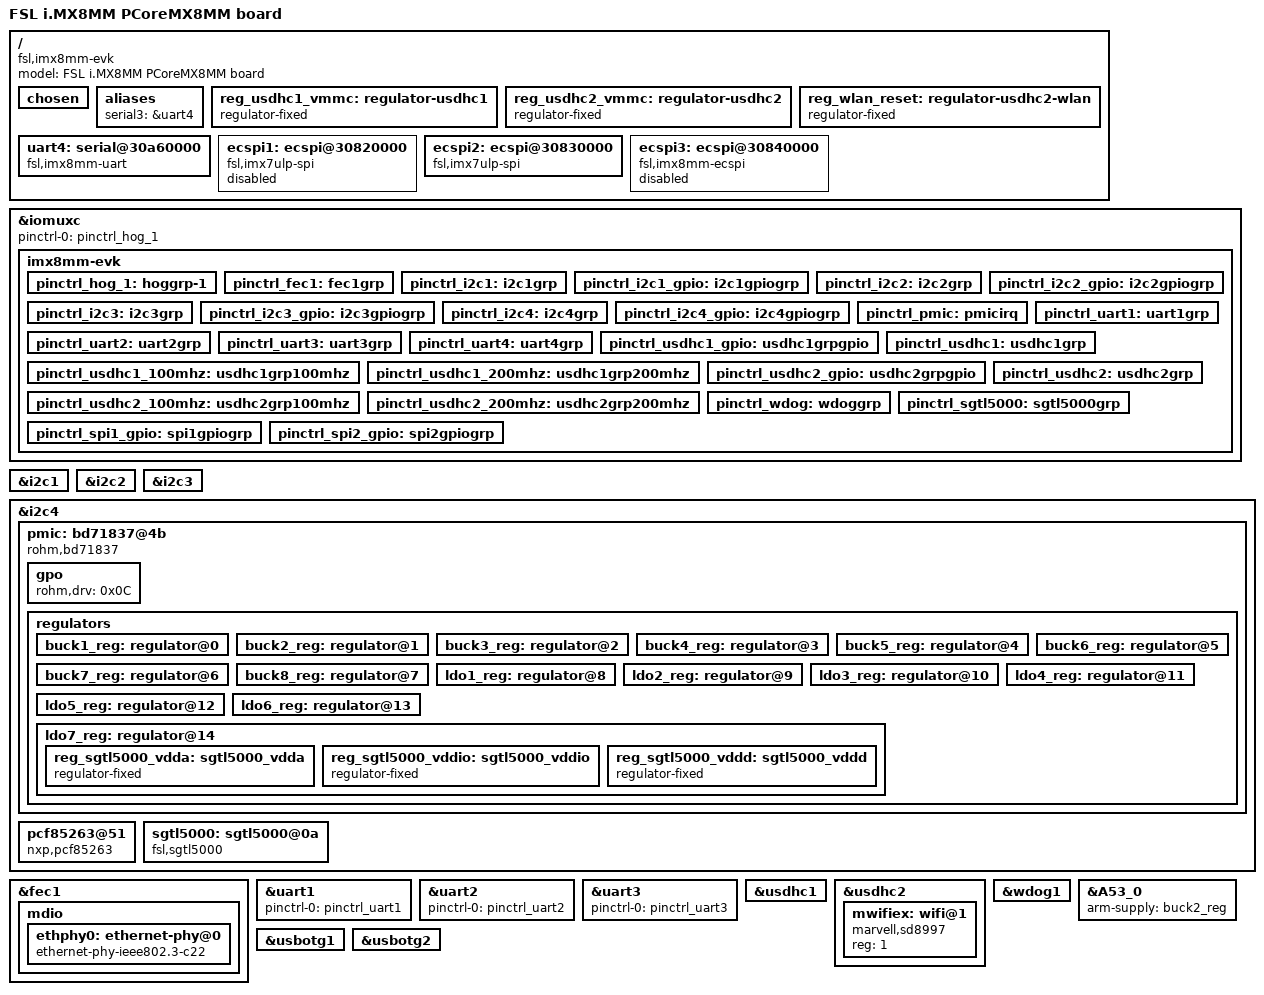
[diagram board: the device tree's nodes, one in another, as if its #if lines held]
/*
 * Copyright 2018 NXP
 *
 * This program is free software; you can redistribute it and/or
 * modify it under the terms of the GNU General Public License
 * as published by the Free Software Foundation; either version 2
 * of the License, or (at your option) any later version.
 *
 * This program is distributed in the hope that it will be useful,
 * but WITHOUT ANY WARRANTY; without even the implied warranty of
 * MERCHANTABILITY or FITNESS FOR A PARTICULAR PURPOSE.  See the
 * GNU General Public License for more details.
 */

/dts-v1/;

/* WLAN/BLUETOOTH; either WLAN-only or combined WLAN/Bluetooth chip */
#define CONFIG_PICOCOREMX8MM_WLAN

/* If WLAN is equipped, SD_B is not available */
#ifdef CONFIG_PICOCOREMX8MM_WLAN
#undef CONFIG_PICOCOREMX8MM_SD_B
#undef CONFIG_PICOCOREMX8MM_SD_B_CD
#undef CONFIG_PICOCOREMX8MM_SD_B_WP
#endif

#include "fsl-imx8mm.dtsi"

/ {

	model = "FSL i.MX8MM PCoreMX8MM board";
	compatible = "fsl,imx8mm-evk", "fsl,imx8mm";

	chosen {
		bootargs = "console=ttymxc1,115200 earlycon=ec_imx6q,0x30890000,115200";
		stdout-path = &uart2;
	};

	aliases {
		serial3 = &uart4;
	};

	reg_usdhc1_vmmc: regulator-usdhc1 {
		compatible = "regulator-fixed";
		regulator-name = "VSD1_3V3";
		regulator-min-microvolt = <3300000>;
		regulator-max-microvolt = <3300000>;
		gpio = <&gpio2 10 GPIO_ACTIVE_HIGH>;
		enable-active-high;
		startup-delay-us = <100>;
		off-on-delay-us = <12000>;
	};

	reg_usdhc2_vmmc: regulator-usdhc2 {
		compatible = "regulator-fixed";
		regulator-name = "VSD2_3V3";
		regulator-min-microvolt = <3300000>;
		regulator-max-microvolt = <3300000>;
		gpio = <&gpio2 19 GPIO_ACTIVE_HIGH>;
		enable-active-high;
		startup-delay-us = <100>;
		off-on-delay-us = <12000>;
	};

	reg_wlan_reset: regulator-usdhc2-wlan {
		compatible = "regulator-fixed";
		regulator-name = "WLAN_RESET";
		regulator-min-microvolt = <3300000>;
		regulator-max-microvolt = <3300000>;
		gpio = <&gpio3 20 GPIO_ACTIVE_HIGH>;
		off-on-delay = <1000>;
		enable-active-high;
	};

	uart4: serial@30a60000 {
		compatible = "fsl,imx8mm-uart",
			     "fsl,imx6q-uart", "fsl,imx21-uart";
		reg = <0x0 0x30a60000 0x0 0x10000>;
		interrupts = <GIC_SPI 29 IRQ_TYPE_LEVEL_HIGH>;
		clocks = <&clk IMX8MM_CLK_UART4_ROOT>,
			<&clk IMX8MM_CLK_UART4_ROOT>;
		clock-names = "ipg", "per";
		dmas = <&sdma1 28 4 0>, <&sdma1 29 4 0>;
		dma-names = "rx", "tx";
		status = "disabled";
	};
	ecspi1: ecspi@30820000 {
		#address-cells = <1>;
		#size-cells = <0>;
		compatible = "fsl,imx8mm-ecspi", "fsl,imx51-ecspi";
		reg = <0x0 0x30820000 0x0 0x10000>;
		interrupts = <GIC_SPI 31 IRQ_TYPE_LEVEL_HIGH>;
		clocks = <&clk IMX8MM_CLK_ECSPI1_ROOT>,
			<&clk IMX8MM_CLK_ECSPI1_ROOT>;
		clock-names = "ipg", "per";
		dmas = <&sdma1 0 7 1>, <&sdma1 1 7 2>;
		dma-names = "rx", "tx";
		status = "disabled";
	};

	ecspi2: ecspi@30830000 {
		#address-cells = <1>;
		#size-cells = <0>;
		compatible = "fsl,imx8mm-ecspi", "fsl,imx51-ecspi";
		reg = <0x0 0x30830000 0x0 0x10000>;
		interrupts = <GIC_SPI 32 IRQ_TYPE_LEVEL_HIGH>;
		clocks = <&clk IMX8MM_CLK_ECSPI2_ROOT>,
			<&clk IMX8MM_CLK_ECSPI2_ROOT>;
		clock-names = "ipg", "per";
		dmas = <&sdma1 2 7 1>, <&sdma1 3 7 2>;
		dma-names = "rx", "tx";
		status = "disabled";
	};

	ecspi3: ecspi@30840000 {
		#address-cells = <1>;
		#size-cells = <0>;
		compatible = "fsl,imx8mm-ecspi", "fsl,imx51-ecspi";
		reg = <0x0 0x30840000 0x0 0x10000>;
		interrupts = <GIC_SPI 33 IRQ_TYPE_LEVEL_HIGH>;
		clocks = <&clk IMX8MM_CLK_ECSPI3_ROOT>,
			<&clk IMX8MM_CLK_ECSPI3_ROOT>;
		clock-names = "ipg", "per";
		dmas = <&sdma1 4 7 1>, <&sdma1 5 7 2>;
		dma-names = "rx", "tx";
		status = "disabled";
	};
};

&iomuxc {
	pinctrl-names = "default";
	pinctrl-0 = <&pinctrl_hog_1>;

	imx8mm-evk {
		pinctrl_hog_1: hoggrp-1 {
			fsl,pins = <
				MX8MM_IOMUXC_GPIO1_IO08_GPIO1_IO8		0x19
				/* CLKO2 -> EXTCLK */
				MX8MM_IOMUXC_GPIO1_IO15_CCMSRCGPCMIX_CLKO2	0x59
			>;
		};

		pinctrl_fec1: fec1grp {
			fsl,pins = <
				MX8MM_IOMUXC_ENET_MDC_ENET1_MDC		0x3
				MX8MM_IOMUXC_ENET_MDIO_ENET1_MDIO	0x3
				MX8MM_IOMUXC_ENET_TD3_ENET1_RGMII_TD3	0x1f
				MX8MM_IOMUXC_ENET_TD2_ENET1_RGMII_TD2	0x1f
				MX8MM_IOMUXC_ENET_TD1_ENET1_RGMII_TD1	0x1f
				MX8MM_IOMUXC_ENET_TD0_ENET1_RGMII_TD0	0x1f
				MX8MM_IOMUXC_ENET_RD3_ENET1_RGMII_RD3	0x91
				MX8MM_IOMUXC_ENET_RD2_ENET1_RGMII_RD2	0x91
				MX8MM_IOMUXC_ENET_RD1_ENET1_RGMII_RD1	0x91
				MX8MM_IOMUXC_ENET_RD0_ENET1_RGMII_RD0	0x91
				MX8MM_IOMUXC_ENET_TXC_ENET1_RGMII_TXC	0x1f
				MX8MM_IOMUXC_ENET_RXC_ENET1_RGMII_RXC	0x91
				MX8MM_IOMUXC_ENET_RX_CTL_ENET1_RGMII_RX_CTL	0x91
				MX8MM_IOMUXC_ENET_TX_CTL_ENET1_RGMII_TX_CTL	0x1f
				MX8MM_IOMUXC_GPIO1_IO04_GPIO1_IO4	0x19
				MX8MM_IOMUXC_GPIO1_IO05_GPIO1_IO5	0x19
			>;
		};

		pinctrl_i2c1: i2c1grp {
			fsl,pins = <
				MX8MM_IOMUXC_I2C1_SCL_I2C1_SCL			0x400001c3
				MX8MM_IOMUXC_I2C1_SDA_I2C1_SDA			0x400001c3
			>;
		};

		pinctrl_i2c1_gpio: i2c1gpiogrp {
			fsl,pins = <
				MX8MM_IOMUXC_I2C1_SCL_GPIO5_IO14			0x119
				MX8MM_IOMUXC_I2C1_SDA_GPIO5_IO15			0x119
			>;
		};

		pinctrl_i2c2: i2c2grp {
			fsl,pins = <
				MX8MM_IOMUXC_I2C2_SCL_I2C2_SCL			0x400001c3
				MX8MM_IOMUXC_I2C2_SDA_I2C2_SDA			0x400001c3
			>;
		};

		pinctrl_i2c2_gpio: i2c2gpiogrp {
			fsl,pins = <
				MX8MM_IOMUXC_I2C2_SCL_GPIO5_IO16			0x119
				MX8MM_IOMUXC_I2C2_SDA_GPIO5_IO17			0x119
			>;
		};

		pinctrl_i2c3: i2c3grp {
			fsl,pins = <
				MX8MM_IOMUXC_I2C3_SCL_I2C3_SCL			0x400001c3
				MX8MM_IOMUXC_I2C3_SDA_I2C3_SDA			0x400001c3
			>;
		};

		pinctrl_i2c3_gpio: i2c3gpiogrp {
			fsl,pins = <
				MX8MM_IOMUXC_I2C3_SCL_GPIO5_IO18			0x119
				MX8MM_IOMUXC_I2C3_SDA_GPIO5_IO19			0x119
			>;
		};

		pinctrl_i2c4: i2c4grp {
			fsl,pins = <
				MX8MM_IOMUXC_I2C4_SCL_I2C4_SCL			0x400001c3
				MX8MM_IOMUXC_I2C4_SDA_I2C4_SDA			0x400001c3
			>;
		};

		pinctrl_i2c4_gpio: i2c4gpiogrp {
			fsl,pins = <
				MX8MM_IOMUXC_I2C4_SCL_GPIO5_IO20			0x119
				MX8MM_IOMUXC_I2C4_SDA_GPIO5_IO21			0x119
			>;
		};

		pinctrl_pmic: pmicirq {
			fsl,pins = <
				MX8MM_IOMUXC_SAI5_RXD3_GPIO3_IO24		0x41
			>;
		};


		pinctrl_uart1: uart1grp {
			fsl,pins = <
				MX8MM_IOMUXC_UART1_RXD_UART1_DCE_RX	0x49
				MX8MM_IOMUXC_UART1_TXD_UART1_DCE_TX	0x49
			>;
		};

		pinctrl_uart2: uart2grp {
			fsl,pins = <
				MX8MM_IOMUXC_UART2_RXD_UART2_DCE_RX	0x49
				MX8MM_IOMUXC_UART2_TXD_UART2_DCE_TX	0x49
			>;
		};

		pinctrl_uart3: uart3grp {
			fsl,pins = <
				MX8MM_IOMUXC_UART3_RXD_UART3_DCE_RX	0x49
				MX8MM_IOMUXC_UART3_TXD_UART3_DCE_TX	0x49
			>;
		};

		pinctrl_uart4: uart4grp {
			fsl,pins = <
				MX8MM_IOMUXC_UART4_RXD_UART4_DCE_RX	0x49
				MX8MM_IOMUXC_UART4_TXD_UART4_DCE_TX	0x49
			>;
		};

       pinctrl_usdhc1_gpio: usdhc1grpgpio {
			fsl,pins = <
                MX8MM_IOMUXC_GPIO1_IO06_USDHC1_CD_B	0x41
				MX8MM_IOMUXC_SD1_RESET_B_GPIO2_IO10	0x41
			>;
		};

		pinctrl_usdhc1: usdhc1grp {
			fsl,pins = <
				MX8MM_IOMUXC_SD1_CLK_USDHC1_CLK		0x190
				MX8MM_IOMUXC_SD1_CMD_USDHC1_CMD		0x1d0
				MX8MM_IOMUXC_SD1_DATA0_USDHC1_DATA0	0x1d0
				MX8MM_IOMUXC_SD1_DATA1_USDHC1_DATA1	0x1d0
				MX8MM_IOMUXC_SD1_DATA2_USDHC1_DATA2	0x1d0
				MX8MM_IOMUXC_SD1_DATA3_USDHC1_DATA3	0x1d0
				MX8MM_IOMUXC_GPIO1_IO03_USDHC1_VSELECT	0x1d0
			>;
		};

		pinctrl_usdhc1_100mhz: usdhc1grp100mhz {
			fsl,pins = <
				MX8MM_IOMUXC_SD1_CLK_USDHC1_CLK		0x194
				MX8MM_IOMUXC_SD1_CMD_USDHC1_CMD		0x1d4
				MX8MM_IOMUXC_SD1_DATA0_USDHC1_DATA0	0x1d4
				MX8MM_IOMUXC_SD1_DATA1_USDHC1_DATA1	0x1d4
				MX8MM_IOMUXC_SD1_DATA2_USDHC1_DATA2	0x1d4
				MX8MM_IOMUXC_SD1_DATA3_USDHC1_DATA3	0x1d4
				MX8MM_IOMUXC_GPIO1_IO03_USDHC1_VSELECT	0x1d0
			>;
		};

		pinctrl_usdhc1_200mhz: usdhc1grp200mhz {
			fsl,pins = <
				MX8MM_IOMUXC_SD1_CLK_USDHC1_CLK		0x196
				MX8MM_IOMUXC_SD1_CMD_USDHC1_CMD		0x1d6
				MX8MM_IOMUXC_SD1_DATA0_USDHC1_DATA0	0x1d6
				MX8MM_IOMUXC_SD1_DATA1_USDHC1_DATA1	0x1d6
				MX8MM_IOMUXC_SD1_DATA2_USDHC1_DATA2	0x1d6
				MX8MM_IOMUXC_SD1_DATA3_USDHC1_DATA3	0x1d6
				MX8MM_IOMUXC_GPIO1_IO03_USDHC1_VSELECT	0x1d0
			>;
		};

		pinctrl_usdhc2_gpio: usdhc2grpgpio {
			fsl,pins = <
                MX8MM_IOMUXC_SD2_CD_B_GPIO2_IO12    0x41
				MX8MM_IOMUXC_SD2_RESET_B_GPIO2_IO19	0x41
			//	MX8MM_IOMUXC_SAI5_RXC_GPIO3_IO20	0x41
			>;
		};

		pinctrl_usdhc2: usdhc2grp {
			fsl,pins = <
				MX8MM_IOMUXC_SD2_CLK_USDHC2_CLK		0x190
				MX8MM_IOMUXC_SD2_CMD_USDHC2_CMD		0x1d0
				MX8MM_IOMUXC_SD2_DATA0_USDHC2_DATA0	0x1d0
				MX8MM_IOMUXC_SD2_DATA1_USDHC2_DATA1	0x1d0
				MX8MM_IOMUXC_SD2_DATA2_USDHC2_DATA2	0x1d0
				MX8MM_IOMUXC_SD2_DATA3_USDHC2_DATA3	0x1d0
				MX8MM_IOMUXC_GPIO1_IO04_USDHC2_VSELECT	0x1d0
			>;
		};

		pinctrl_usdhc2_100mhz: usdhc2grp100mhz {
			fsl,pins = <
				MX8MM_IOMUXC_SD2_CLK_USDHC2_CLK		0x194
				MX8MM_IOMUXC_SD2_CMD_USDHC2_CMD		0x1d4
				MX8MM_IOMUXC_SD2_DATA0_USDHC2_DATA0	0x1d4
				MX8MM_IOMUXC_SD2_DATA1_USDHC2_DATA1	0x1d4
				MX8MM_IOMUXC_SD2_DATA2_USDHC2_DATA2	0x1d4
				MX8MM_IOMUXC_SD2_DATA3_USDHC2_DATA3	0x1d4
				MX8MM_IOMUXC_GPIO1_IO04_USDHC2_VSELECT	0x1d0
			>;
		};

		pinctrl_usdhc2_200mhz: usdhc2grp200mhz {
			fsl,pins = <
				MX8MM_IOMUXC_SD2_CLK_USDHC2_CLK		0x196
				MX8MM_IOMUXC_SD2_CMD_USDHC2_CMD		0x1d6
				MX8MM_IOMUXC_SD2_DATA0_USDHC2_DATA0	0x1d6
				MX8MM_IOMUXC_SD2_DATA1_USDHC2_DATA1	0x1d6
				MX8MM_IOMUXC_SD2_DATA2_USDHC2_DATA2	0x1d6
				MX8MM_IOMUXC_SD2_DATA3_USDHC2_DATA3	0x1d6
				MX8MM_IOMUXC_GPIO1_IO04_USDHC2_VSELECT	0x1d0
			>;
		};


		pinctrl_wdog: wdoggrp {
			fsl,pins = <
				MX8MM_IOMUXC_SAI1_RXD7_GPIO4_IO9		0xc6
			>;
		};

		pinctrl_sgtl5000: sgtl5000grp {
			fsl,pins = <
				MX8MM_IOMUXC_SAI1_MCLK_SAI1_MCLK		0x000d6
				MX8MM_IOMUXC_SAI1_TXFS_SAI1_TX_SYNC		0x000d6
				MX8MM_IOMUXC_SAI1_TXC_SAI1_TX_BCLK		0x000d6
				MX8MM_IOMUXC_SAI1_TXD0_SAI1_TX_DATA0		0x000d6
				MX8MM_IOMUXC_SAI1_RXD0_SAI1_RX_DATA0		0x000d6
			>;
		};


		pinctrl_spi1_gpio: spi1gpiogrp {
            fsl,pins = <

                MX8MM_IOMUXC_ECSPI1_SCLK_GPIO5_IO6    0x119
                MX8MM_IOMUXC_ECSPI1_MOSI_GPIO5_IO7    0x119
                MX8MM_IOMUXC_ECSPI1_MISO_GPIO5_IO8    0x119
                MX8MM_IOMUXC_ECSPI1_SS0_GPIO5_IO9     0x119
            >;
        };
            pinctrl_spi2_gpio: spi2gpiogrp {
            fsl,pins = <

                MX8MM_IOMUXC_ECSPI2_SCLK_GPIO5_IO10    0x119
                MX8MM_IOMUXC_ECSPI2_MOSI_GPIO5_IO11    0x119
                MX8MM_IOMUXC_ECSPI2_MISO_GPIO5_IO12    0x119
                MX8MM_IOMUXC_ECSPI2_SS0_GPIO5_IO13     0x119
            >;
        };

	};
};

&i2c1 {
	clock-frequency = <400000>;
    pinctrl-names = "default", "gpiotest";
    pinctrl-0 = <&pinctrl_i2c1>;
	pinctrl-1 = <&pinctrl_i2c1_gpio>;
    out-pins = "I2C_A_SCL";
    out-gpios = <&gpio5 14 0>;
    in-pins = "I2C_A_SDA";
    in-gpios = <&gpio5 15 0>;
    status = "okay";
};

&i2c2 {
	clock-frequency = <400000>;
	pinctrl-names = "default";
	pinctrl-0 = <&pinctrl_i2c2>;
	pinctrl-1 = <&pinctrl_i2c2_gpio>;
    out-pins = "I2C_B_SCL";
    out-gpios = <&gpio5 16 0>;
    in-pins = "I2C_B_SDA";
    in-gpios = <&gpio5 17 0>;
	status = "okay";
};

&i2c3 {
	clock-frequency = <100000>;
	pinctrl-names = "default";
	pinctrl-0 = <&pinctrl_i2c3>;
	pinctrl-1 = <&pinctrl_i2c3_gpio>;
    out-pins = "I2C_C_SCL";
    out-gpios = <&gpio5 18 0>;
    in-pins = "I2C_C_SDA";
    in-gpios = <&gpio5 19 0>;
	status = "okay";
};

&i2c4 {
	clock-frequency = <400000>;
	pinctrl-names = "default";
	pinctrl-0 = <&pinctrl_i2c4>;
	pinctrl-1 = <&pinctrl_i2c4_gpio>;
    out-pins = "I2C_D_SCL";
    out-gpios = <&gpio5 20 0>;
    in-pins = "I2C_D_SDA";
    in-gpios = <&gpio5 21 0>;
	status = "okay";

	pmic: bd71837@4b {
		reg = <0x4b>;
		compatible = "rohm,bd71837";
		/* PMIC BD71837 PMIC_nINT GPIO3_IO24 */
		pinctrl-0 = <&pinctrl_pmic>;
		gpio_intr = <&gpio3 24 GPIO_ACTIVE_LOW>;
		status = "okay";

		gpo {
			rohm,drv = <0x0C>;	/* 0b0000_1100 all gpos with cmos output mode */
		};

		regulators {
			#address-cells = <1>;
			#size-cells = <0>;

			bd71837,pmic-buck2-uses-i2c-dvs;
			bd71837,pmic-buck2-dvs-voltage = <1000000>, <900000>, <0>; /* VDD_ARM: Run-Idle */

			buck1_reg: regulator@0 {
				reg = <0>;
				regulator-compatible = "buck1";
				regulator-min-microvolt = <700000>;
				regulator-max-microvolt = <1300000>;
				regulator-boot-on;
				regulator-always-on;
				regulator-ramp-delay = <1250>;
			};

			buck2_reg: regulator@1 {
				reg = <1>;
				regulator-compatible = "buck2";
				regulator-min-microvolt = <700000>;
				regulator-max-microvolt = <1300000>;
				regulator-boot-on;
				regulator-always-on;
				regulator-ramp-delay = <1250>;
			};

			buck3_reg: regulator@2 {
				reg = <2>;
				regulator-compatible = "buck3";
				regulator-min-microvolt = <700000>;
				regulator-max-microvolt = <1300000>;
			};

			buck4_reg: regulator@3 {
				reg = <3>;
				regulator-compatible = "buck4";
				regulator-min-microvolt = <700000>;
				regulator-max-microvolt = <1300000>;
			};

			buck5_reg: regulator@4 {
				reg = <4>;
				regulator-compatible = "buck5";
				regulator-min-microvolt = <700000>;
				regulator-max-microvolt = <1350000>;
				regulator-boot-on;
				regulator-always-on;
			};

			buck6_reg: regulator@5 {
				reg = <5>;
				regulator-compatible = "buck6";
				regulator-min-microvolt = <3000000>;
				regulator-max-microvolt = <3300000>;
				regulator-boot-on;
				regulator-always-on;
			};

			buck7_reg: regulator@6 {
				reg = <6>;
				regulator-compatible = "buck7";
				regulator-min-microvolt = <1605000>;
				regulator-max-microvolt = <1995000>;
				regulator-boot-on;
				regulator-always-on;
			};

			buck8_reg: regulator@7 {
				reg = <7>;
				regulator-compatible = "buck8";
				regulator-min-microvolt = <800000>;
				regulator-max-microvolt = <1400000>;
				regulator-boot-on;
				regulator-always-on;
			};

			ldo1_reg: regulator@8 {
				reg = <8>;
				regulator-compatible = "ldo1";
				regulator-min-microvolt = <3000000>;
				regulator-max-microvolt = <3300000>;
				regulator-boot-on;
				regulator-always-on;
			};

			ldo2_reg: regulator@9 {
				reg = <9>;
				regulator-compatible = "ldo2";
				regulator-min-microvolt = <900000>;
				regulator-max-microvolt = <900000>;
				regulator-boot-on;
				regulator-always-on;
			};

			ldo3_reg: regulator@10 {
				reg = <10>;
				regulator-compatible = "ldo3";
				regulator-min-microvolt = <1800000>;
				regulator-max-microvolt = <3300000>;
				regulator-boot-on;
				regulator-always-on;
			};

			ldo4_reg: regulator@11 {
				reg = <11>;
				regulator-compatible = "ldo4";
				regulator-min-microvolt = <900000>;
				regulator-max-microvolt = <1800000>;
				regulator-boot-on;
				regulator-always-on;
			};

			ldo5_reg: regulator@12 {
				reg = <12>;
				regulator-compatible = "ldo5";
				regulator-min-microvolt = <1800000>;
				regulator-max-microvolt = <3300000>;
			};

			ldo6_reg: regulator@13 {
				reg = <13>;
				regulator-compatible = "ldo6";
				regulator-min-microvolt = <900000>;
				regulator-max-microvolt = <1800000>;
				regulator-boot-on;
				regulator-always-on;
			};

			ldo7_reg: regulator@14 {
				reg = <14>;
				regulator-compatible = "ldo7";
				regulator-min-microvolt = <1800000>;
				regulator-max-microvolt = <3300000>;
			/* SGTL5000 analog voltage */
			reg_sgtl5000_vdda: sgtl5000_vdda {
				compatible = "regulator-fixed";
				regulator-name = "VDDA-supply";
				regulator-min-microvolt = <3000000>;
				regulator-max-microvolt = <3000000>;
				regulator-always-on;
			};

			/* SGTL5000 I/O voltage */
			reg_sgtl5000_vddio: sgtl5000_vddio {
				compatible = "regulator-fixed";
				regulator-name = "VDDIO-supply";
				regulator-min-microvolt = <3300000>;
				regulator-max-microvolt = <3300000>;
				regulator-always-on;
			};

			/* SGTL5000 internal digital voltage */
			reg_sgtl5000_vddd: sgtl5000_vddd {
				compatible = "regulator-fixed";
				regulator-name = "VDDD-supply";
				regulator-min-microvolt = <1500000>;
				regulator-max-microvolt = <1500000>;
				regulator-always-on;
			};
			};
		};
	};

	pcf85263@51 {
 		compatible = "nxp,pcf85263";
		quartz-load-capacitance = <0x2>; /* 12.5 pF */
		reg = <0x51>;
		status = "okay";
	};

	sgtl5000: sgtl5000@0a {
		compatible = "fsl,sgtl5000";
		/* MCLK is needed for i2c sgtl driver */
		pinctrl-names = "default";
		pinctrl-0 = <&pinctrl_sgtl5000>;
		reg = <0x0a>;
		status = "okay";
	};
};

&fec1 {
	pinctrl-names = "default";
	pinctrl-0 = <&pinctrl_fec1>;
	phy-mode = "rgmii-id";
	phy-handle = <&ethphy0>;
	fsl,magic-packet;
	status = "okay";
    phy-reset-gpios = <&gpio1 5 GPIO_ACTIVE_LOW>;
    phy-reset-duration = <50>;
    phy-reset-post-delay = <200>;


	mdio {
		#address-cells = <1>;
		#size-cells = <0>;

		ethphy0: ethernet-phy@0 {
			compatible = "ethernet-phy-ieee802.3-c22";
			reg = <0>;
			at803x,led-act-blind-workaround;
			at803x,eee-okay;
#if 0
			at803x,vddio-1p8v;
#endif
		};
	};
};

&uart1 { /* console */
	pinctrl-names = "default";
	pinctrl-0 = <&pinctrl_uart1>;
	status = "okay";
};

&uart2 { /* console */
	pinctrl-names = "default";
	pinctrl-0 = <&pinctrl_uart2>;
	status = "okay";
};

&uart3 { /* console */
	pinctrl-names = "default";
	pinctrl-0 = <&pinctrl_uart3>;
	status = "okay";
};

&uart4 { /* console */
	pinctrl-names = "default";
	pinctrl-0 = <&pinctrl_uart4>;
	status = "okay";
};

&usdhc1 {
	pinctrl-names = "default", "state_100mhz", "state_200mhz";
	pinctrl-0 = <&pinctrl_usdhc1>, <&pinctrl_usdhc1_gpio>;
	pinctrl-1 = <&pinctrl_usdhc1_100mhz>, <&pinctrl_usdhc1_gpio>;
	pinctrl-2 = <&pinctrl_usdhc1_200mhz>, <&pinctrl_usdhc1_gpio>;
	bus-width = <4>;
	cd-gpios = <&gpio1 6 GPIO_ACTIVE_LOW>;
	vmmc-supply = <&reg_usdhc1_vmmc>;
	is-sdcard;
	status = "okay";
};

/* WLAN */
#if defined(CONFIG_PICOCOREMX8MM_WLAN) || defined(CONFIG_PICOCOREMX8MM_SD_B)
&usdhc2 {
	pinctrl-names = "default", "state_100mhz", "state_200mhz";
	pinctrl-0 = <&pinctrl_usdhc2>, <&pinctrl_usdhc2_gpio>;
	pinctrl-1 = <&pinctrl_usdhc2_100mhz>, <&pinctrl_usdhc2_gpio>;
	pinctrl-2 = <&pinctrl_usdhc2_200mhz>, <&pinctrl_usdhc2_gpio>;
#ifdef CONFIG_PICOCOREMX8MM_SD_B_CD
	cd-gpios = <&gpio2 12 GPIO_ACTIVE_LOW>;
#else
	non-removable;
#endif
#ifdef CONFIG_PICOCOREMX8MM_SD_B_WP
	wp-gpios = <&gpio2 20 GPIO_ACTIVE_HIGH>;
#endif
	bus-width = <4>;
#ifdef CONFIG_PICOCOREMX8MM_WLAN
	vmmc-supply = <&reg_wlan_reset>;
#else
	vmmc-supply = <&reg_usdhc2_vmmc>;
#endif
	voltage-ranges = <3300 3300>;
	no-1-8-v;
	keep-power-in-suspend;
#ifdef CONFIG_PICOCOREMX8MM_WLAN
	enable-sdio-wakeup;
	cap-power-off-card;
	is-wlan;
#endif
	status = "okay";

	#address-cells = <1>;
	#size-cells = <0>;
	mwifiex: wifi@1 {
		compatible = "marvell,sd8997";
		reg = <1>;
	};
};
#endif


&wdog1 {
	pinctrl-names = "default";
	pinctrl-0 = <&pinctrl_wdog>;
	fsl,ext-reset-output;
	status = "okay";
};

&A53_0 {
	arm-supply = <&buck2_reg>;
};

&usbotg1 {
	status = "okay";
};

&usbotg2 {
	status = "okay";
};

&ecspi1 {
	compatible = "fsl,imx7ulp-spi";
    pinctrl-names = "gpiotest";
    pinctrl-0 = <&pinctrl_spi1_gpio>;
    out-pins = "SPI_A_MOSI", "SPI_A_CS1";
    out-gpios = <&gpio5 7 0>, <&gpio5 9 0>;
    in-pins = "SPI_A_MISO", "SPI_B_SCK";
    in-gpios = <&gpio5 8 0>, <&gpio5 6 0>;

	status = "disabled";
};

&ecspi2 {
	compatible = "fsl,imx7ulp-spi";
    pinctrl-names = "gpiotest";
    pinctrl-0 = <&pinctrl_spi2_gpio>;
    out-pins = "SPI_B_MOSI", "SPI_B_CS1";
    out-gpios = <&gpio5 11 0>, <&gpio5 13 0>;
    in-pins = "SPI_B_MISO", "SPI_B_SCK";
    in-gpios = <&gpio5 12 0>, <&gpio5 10 0>;

	status = "okay";
};

